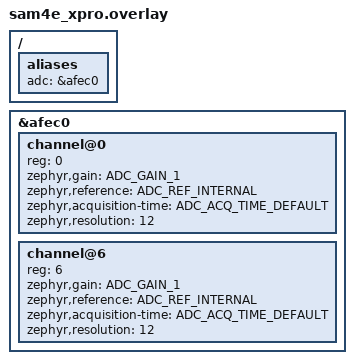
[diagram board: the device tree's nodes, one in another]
/*
 * Copyright (c) 2024 Centro de Inovacao EDGE
 *
 * SPDX-License-Identifier: Apache-2.0
 */

/ {
	aliases {
		adc = &afec0;
	};
};

&afec0 {
	#address-cells = <1>;
	#size-cells = <0>;

	channel@0 {
		reg = <0>;
		zephyr,gain = "ADC_GAIN_1";
		zephyr,reference = "ADC_REF_INTERNAL";
		zephyr,acquisition-time = <ADC_ACQ_TIME_DEFAULT>;
		zephyr,resolution = <12>;
	};

	channel@6 {
		reg = <6>;
		zephyr,gain = "ADC_GAIN_1";
		zephyr,reference = "ADC_REF_INTERNAL";
		zephyr,acquisition-time = <ADC_ACQ_TIME_DEFAULT>;
		zephyr,resolution = <12>;
	};
};
